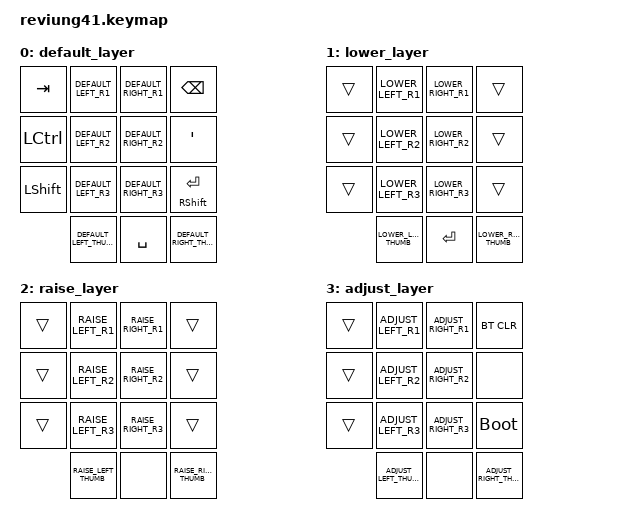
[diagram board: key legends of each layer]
/*
 * Copyright (c) 2023 Hannes Hasselbring
 *
 * SPDX-License-Identifier: MIT
 */

#include <behaviors.dtsi>
#include <dt-bindings/zmk/bt.h>
#include <dt-bindings/zmk/keys.h>

#include "layout.h"
#include "keypos/reviung41.h"

#include "behaviors.dtsi"

/ {
    combos {
       #include "combos.dtsi"
    };

    macros {
        #include "macros.dtsi"
    };

    keymap {
        compatible = "zmk,keymap";

        default_layer {
            bindings = <
&kp TAB    DEFAULT_LEFT_R1             DEFAULT_RIGHT_R1     &kp BSPC
&kp LCTRL  DEFAULT_LEFT_R2             DEFAULT_RIGHT_R2     &kp SQT
&kp LSHFT  DEFAULT_LEFT_R3             DEFAULT_RIGHT_R3     &mt RSHFT RET
         DEFAULT_LEFT_THUMB &kp SPACE  DEFAULT_RIGHT_THUMB
            >;
        };

        lower_layer {
            bindings = <
&trans  LOWER_LEFT_R1           LOWER_RIGHT_R1  &trans
&trans  LOWER_LEFT_R2           LOWER_RIGHT_R2  &trans
&trans  LOWER_LEFT_R3           LOWER_RIGHT_R3  &trans
    LOWER_LEFT_THUMB  &kp RET   LOWER_RIGHT_THUMB
            >;
        };

        raise_layer {
            bindings = <
&trans  RAISE_LEFT_R1            RAISE_RIGHT_R1  &trans
&trans  RAISE_LEFT_R2            RAISE_RIGHT_R2  &trans
&trans  RAISE_LEFT_R3            RAISE_RIGHT_R3  &trans
   RAISE_LEFT_THUMB    &none     RAISE_RIGHT_THUMB
            >;
        };

        adjust_layer {
            bindings = <
&trans  ADJUST_LEFT_R1          ADJUST_RIGHT_R1 &bt BT_CLR
&trans  ADJUST_LEFT_R2          ADJUST_RIGHT_R2 &none
&trans  ADJUST_LEFT_R3          ADJUST_RIGHT_R3 &bootloader
    ADJUST_LEFT_THUMB   &none   ADJUST_RIGHT_THUMB
            >;
        };
    };
};
